# V8M-Generic register map
Vendor: ARM Ltd.
CPU: V8M-Generic r0p0, little endian, MPU, FPU, double-precision FPU, VTOR, vendor SysTick, 8 interrupt priority bits
Registers are 32-bit, read-write, no defined reset value unless marked. A register's access mark holds for its fields unless they carry their own. Offsets are from the block's base; [hi:lo] are bit positions; {n}, {i} and the like mark numbered series; 'fields as' and 'values as' point back to an identical list.

## SCB — System Control Block
Base ?
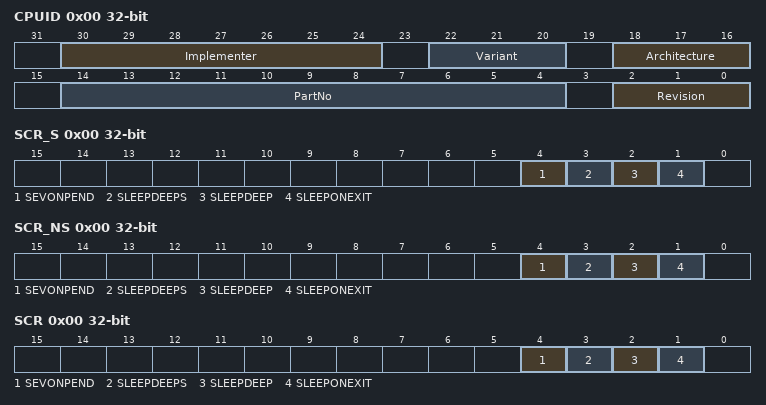
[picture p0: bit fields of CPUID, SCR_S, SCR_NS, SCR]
0x00 CPUID ro
  [30:24] Implementer — Implementer code
  [22:20] Variant — Variant number
  [18:16] Architecture — Architecture version
  [14:4] PartNo — Part number
  [2:0] Revision — Revision number
0x00 SCR_S
  [4] SEVONPEND — Send event on pend
  [3] SLEEPDEEPS — Sleep deep secure
  [2] SLEEPDEEP
  [1] SLEEPONEXIT
0x00 SCR_NS
  fields as SCR_S
0x00 SCR
  fields as SCR_S
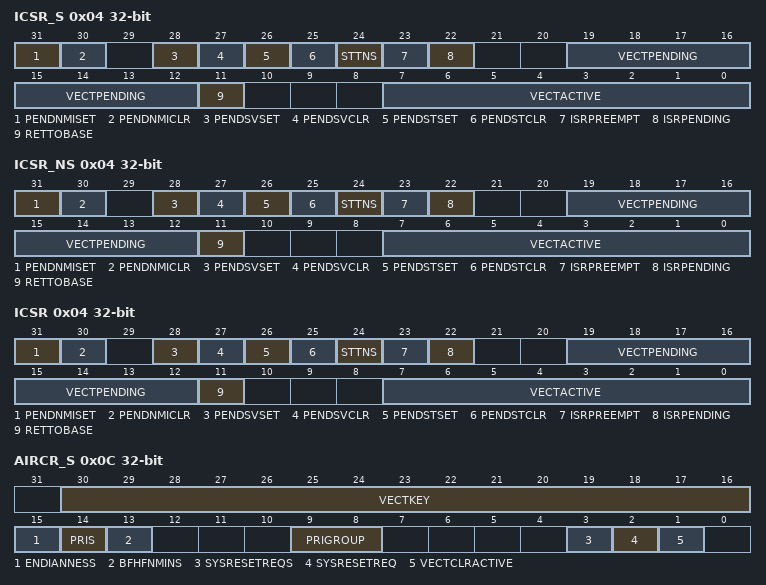
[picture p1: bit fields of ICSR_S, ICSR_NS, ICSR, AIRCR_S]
0x04 ICSR_S
  [31] PENDNMISET
  [30] PENDNMICLR — Pend NMI clear
  [28] PENDSVSET — Pend PendSV set
  [27] PENDSVCLR — Pend PendSV clear
  [26] PENDSTSET — Pend SysTick set
  [25] PENDSTCLR — Pend SysTick clear
  [24] STTNS — SysTick Targets Non-secure
  [23] ISRPREEMPT — Interrupt preempt
  [22] ISRPENDING — Interrupt pending
  [19:12] VECTPENDING — Vector pending
  [11] RETTOBASE — Return to base
  [7:0] VECTACTIVE — Vector active
0x04 ICSR_NS
  fields as ICSR_S
0x04 ICSR
  fields as ICSR_S
0x08 VTOR_S
  [30:7] TBLOFF — Table offset
0x08 VTOR_NS
  [30:7] TBLOFF — Table offset
0x08 VTOR
  [30:7] TBLOFF — Table offset
0x0C AIRCR_S
  [30:16] VECTKEY — Vector key
  [15] ENDIANNESS — Data endianness
  [14] PRIS — Prioritize Secure exceptions
  [13] BFHFNMINS — BusFault, HardFault, and NMI Non-secure enable
  [9:8] PRIGROUP — Priority grouping
  [3] SYSRESETREQS — System reset request Secure only
  [2] SYSRESETREQ — System reset request
  [1] VECTCLRACTIVE — Clear active state
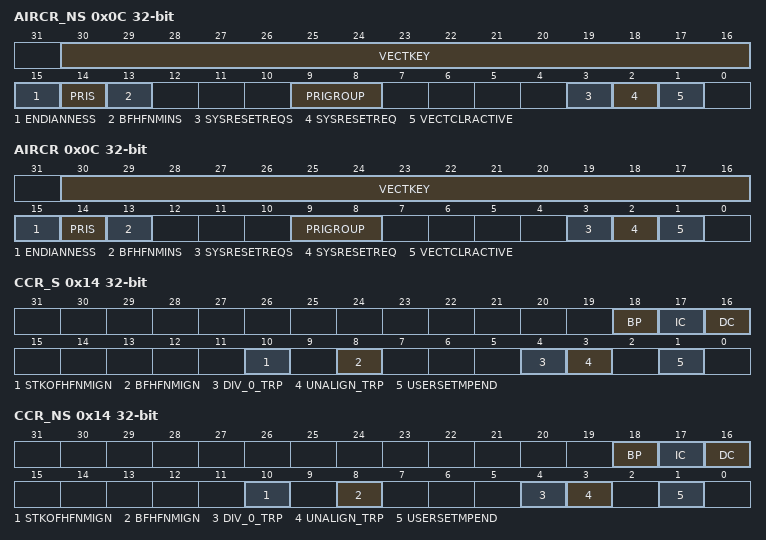
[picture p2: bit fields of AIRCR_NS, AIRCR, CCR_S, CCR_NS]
0x0C AIRCR_NS
  fields as AIRCR_S
0x0C AIRCR
  fields as AIRCR_S
0x14 CCR_S
  [18] BP — Branch prediction enable
  [17] IC — Instruction cache enable
  [16] DC — Data cache enable
  [10] STKOFHFNMIGN — Stack overflow in HardFault and NMI ignore
  [8] BFHFNMIGN — BusFault in HardFault or NMI ignore
  [4] DIV_0_TRP — Divide by zero trap
  [3] UNALIGN_TRP — Unaligned trap
  [1] USERSETMPEND — User set main pending
0x14 CCR_NS
  fields as CCR_S
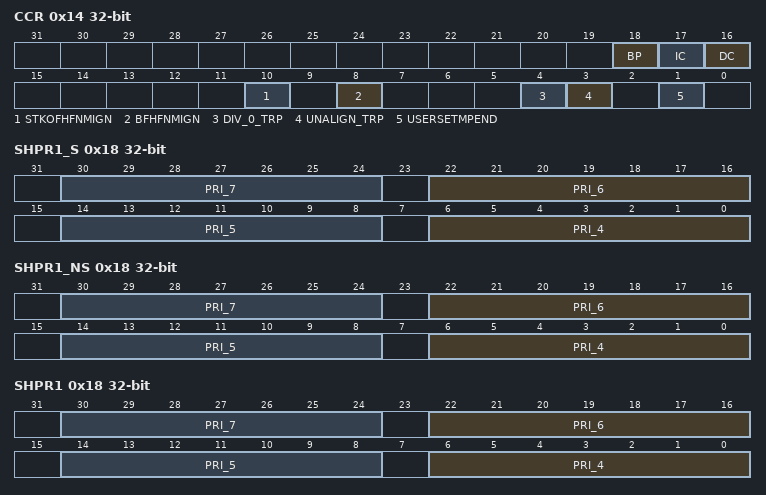
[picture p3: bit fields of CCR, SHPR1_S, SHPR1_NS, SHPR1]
0x14 CCR
  fields as CCR_S
0x18 SHPR1_S
  [8n-26:8n-32] PRI_{n} (n=4..7) — Priority {n}
0x18 SHPR1_NS
  [8n-26:8n-32] PRI_{n} (n=4..7) — Priority {n}
0x18 SHPR1
  [8n-26:8n-32] PRI_{n} (n=4..7) — Priority {n}
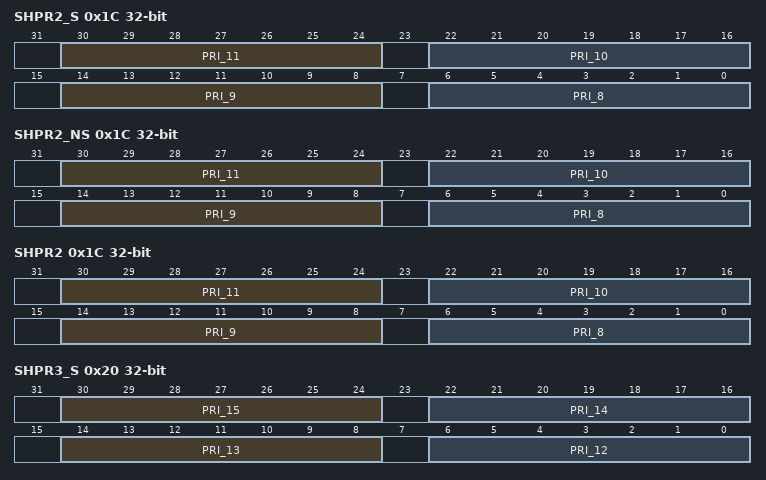
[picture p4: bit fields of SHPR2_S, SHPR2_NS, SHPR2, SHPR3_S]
0x1C SHPR2_S
  [30:24] PRI_11 — Priority 11
  [22:16] PRI_10
  [14:8] PRI_9
  [6:0] PRI_8
0x1C SHPR2_NS
  fields as SHPR2_S
0x1C SHPR2
  fields as SHPR2_S
0x20 SHPR3_S
  [30:24] PRI_15 — Priority 15
  [22:16] PRI_14 — Priority 14
  [14:8] PRI_13
  [6:0] PRI_12 — Priority 12
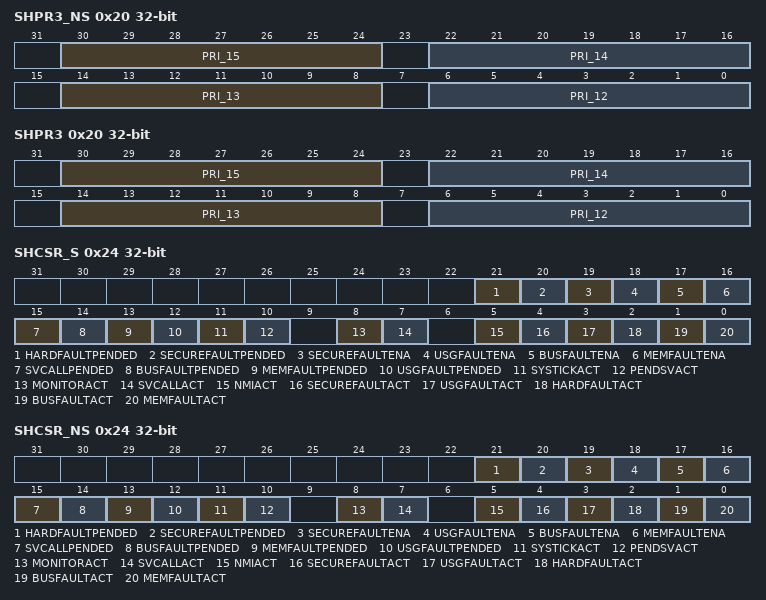
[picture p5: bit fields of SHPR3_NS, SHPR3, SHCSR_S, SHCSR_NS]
0x20 SHPR3_NS
  fields as SHPR3_S
0x20 SHPR3
  fields as SHPR3_S
0x24 SHCSR_S
  [21] HARDFAULTPENDED — HardFault exception pended state
  [20] SECUREFAULTPENDED — SecureFault exception pended state
  [19] SECUREFAULTENA — SecureFault exception enable
  [18] USGFAULTENA — UsageFault exception enable
  [17] BUSFAULTENA — BusFault exception enable
  [16] MEMFAULTENA — MemManage exception enable
  [15] SVCALLPENDED — SVCall exception pended state
  [14] BUSFAULTPENDED — BusFault exception pended state
  [13] MEMFAULTPENDED — MemManage exception pended state
  [12] USGFAULTPENDED — UsageFault exception pended state
  [11] SYSTICKACT — SysTick exception active state
  [10] PENDSVACT — PendSV exception active state
  [8] MONITORACT — DebugMonitor exception active state
  [7] SVCALLACT — SVCall exception active state
  [5] NMIACT — NMI exception active state
  [4] SECUREFAULTACT — SecureFault exception active state
  [3] USGFAULTACT — UsageFault exception active state FTSSS
  [2] HARDFAULTACT — HardFault exception active state
  [1] BUSFAULTACT — BusFault exception active state
  [0] MEMFAULTACT — MemManage exception active state FTSSS
0x24 SHCSR_NS
  fields as SHCSR_S
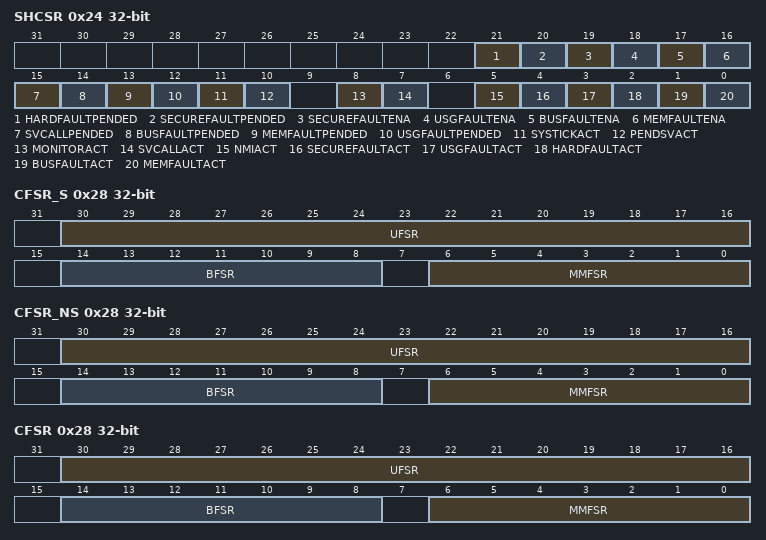
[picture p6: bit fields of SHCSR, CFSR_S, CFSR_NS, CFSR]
0x24 SHCSR
  fields as SHCSR_S
0x28 CFSR_S
  [30:16] UFSR — UsageFault Status Register
  [14:8] BFSR — BusFault Status Register
  [6:0] MMFSR — MemManage Fault Status Register
0x28 CFSR_NS
  fields as CFSR_S
0x28 CFSR
  fields as CFSR_S
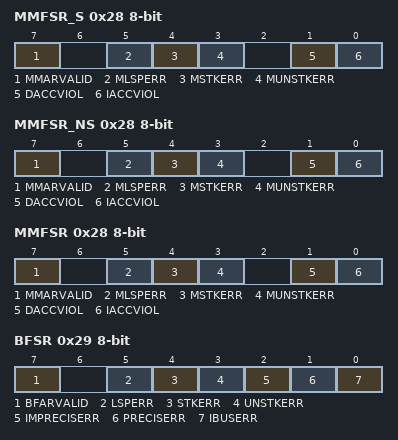
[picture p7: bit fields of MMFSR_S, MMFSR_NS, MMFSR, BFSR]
0x28 MMFSR_S 8-bit
  [7] MMARVALID — MMFAR valid flag
  [5] MLSPERR — MemManage lazy state preservation error flag
  [4] MSTKERR — MemManage stacking error flag
  [3] MUNSTKERR — MemManage unstacking error flag
  [1] DACCVIOL — Data access violation flag
  [0] IACCVIOL — Instruction access violation
0x28 MMFSR_NS 8-bit
  fields as MMFSR_S
0x28 MMFSR 8-bit
  fields as MMFSR_S
0x29 BFSR 8-bit
  [7] BFARVALID
  [5] LSPERR — Lazy state preservation error
  [4] STKERR — Stack error
  [3] UNSTKERR — Unstack error
  [2] IMPRECISERR — Imprecise error
  [1] PRECISERR — Precise error
  [0] IBUSERR — Instruction bus error
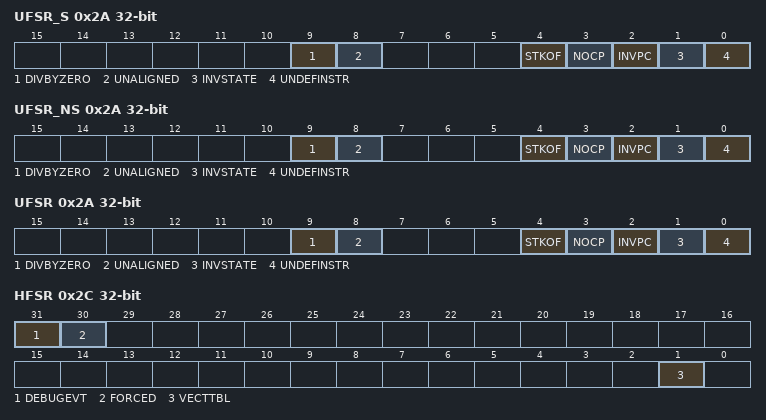
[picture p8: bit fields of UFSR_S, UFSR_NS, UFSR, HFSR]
0x2A UFSR_S size not given
  [9] DIVBYZERO — Divide by zero flag
  [8] UNALIGNED — Unaligned access flag
  [4] STKOF — Stack overflow flag
  [3] NOCP — No coprocessor flag
  [2] INVPC — Invalid PC flag
  [1] INVSTATE — Invalid state flag
  [0] UNDEFINSTR — Undefined instruction flag
0x2A UFSR_NS size not given
  fields as UFSR_S
0x2A UFSR size not given
  fields as UFSR_S
0x2C HFSR
  [31] DEBUGEVT — Debug event
  [30] FORCED
  [1] VECTTBL — Vector table
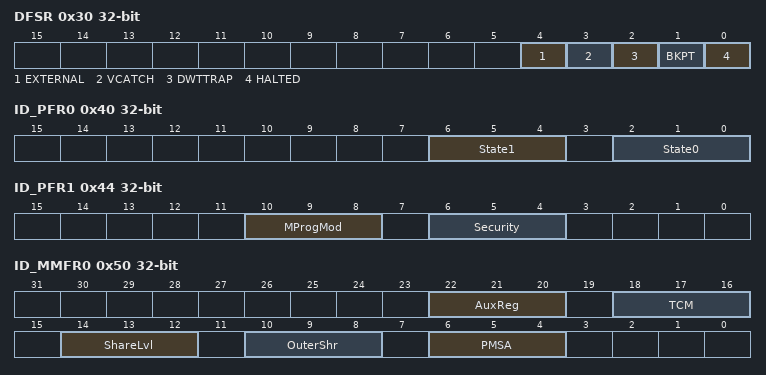
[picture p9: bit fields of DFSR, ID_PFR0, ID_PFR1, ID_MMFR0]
0x30 DFSR
  [4] EXTERNAL — External event
  [3] VCATCH — Vector Catch event
  [2] DWTTRAP — Watchpoint event
  [1] BKPT — Breakpoint event
  [0] HALTED — Halt or step event
0x34 MMFAR_S
  [30:0] ADDRESS — Data address for an MemManage fault
0x34 MMFAR_NS
  [30:0] ADDRESS — Data address for an MemManage fault
0x34 MMFAR
  [30:0] ADDRESS — Data address for an MemManage fault
0x38 BFAR
  [30:0] ADDRESS — Data address for a precise BusFault
0x3C AFSR
0x40 ID_PFR0 ro
  [6:4] State1 — State one
  [2:0] State0 — State two
0x44 ID_PFR1 ro
  [10:8] MProgMod — M programmers' model
  [6:4] Security
0x48 ID_DFR0 ro
  [22:20] MProfDbg — M-profile debug
0x4C ID_AFR0 ro
0x50 ID_MMFR0 ro
  [22:20] AuxReg — Auxiliary Registers
  [18:16] TCM — Tightly coupled memories
  [14:12] ShareLvl — Shareability Levels
  [10:8] OuterShr — Outermost Shareability
  [6:4] PMSA — Protected memory system architecture
0x54 ID_MMFR1 ro
0x58 ID_MMFR2 ro
  [26:24] WFIStall
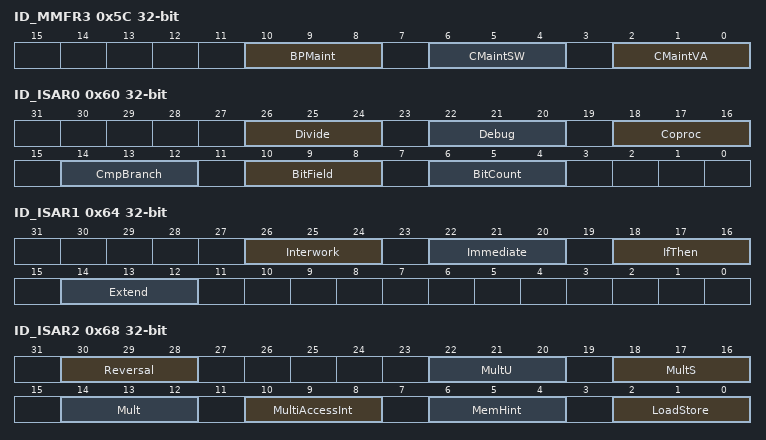
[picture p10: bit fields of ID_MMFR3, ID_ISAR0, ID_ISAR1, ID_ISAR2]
0x5C ID_MMFR3 ro
  [10:8] BPMaint — Branch predictor maintenance
  [6:4] CMaintSW — Cache maintenance set/way
  [2:0] CMaintVA — Cache maintenance by address
0x60 ID_ISAR0 ro
  [26:24] Divide
  [22:20] Debug
  [18:16] Coproc — Coprocessor
  [14:12] CmpBranch — Compare and branch
  [10:8] BitField
  [6:4] BitCount
0x64 ID_ISAR1 ro
  [26:24] Interwork — Interworking
  [22:20] Immediate
  [18:16] IfThen
  [14:12] Extend
0x68 ID_ISAR2 ro
  [30:28] Reversal
  [22:20] MultU — Multiply unsigned
  [18:16] MultS — Multiply signed
  [14:12] Mult — Multiplies
  [10:8] MultiAccessInt — Multi-access instructions
  [6:4] MemHint — Memory hints
  [2:0] LoadStore
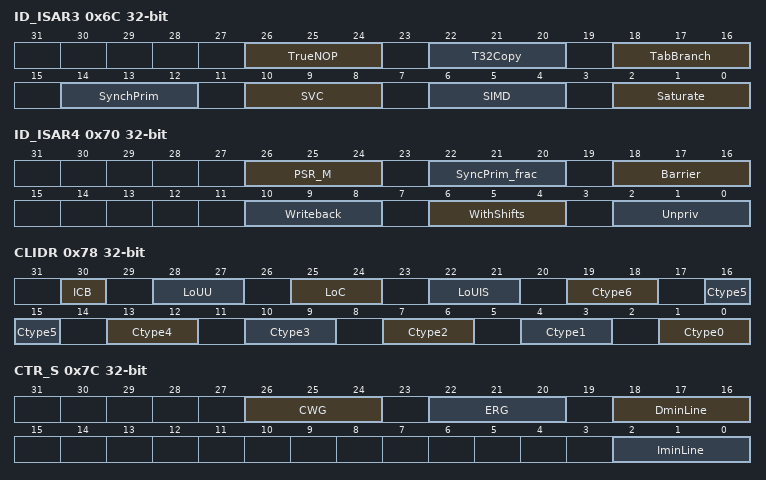
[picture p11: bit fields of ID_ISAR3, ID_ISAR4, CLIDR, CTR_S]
0x6C ID_ISAR3 ro
  [26:24] TrueNOP — True no-operation
  [22:20] T32Copy
  [18:16] TabBranch — Table branch
  [14:12] SynchPrim — Synchronization primitives
  [10:8] SVC — Supervisor call
  [6:4] SIMD — Single-instruction, multiple-data
  [2:0] Saturate
0x70 ID_ISAR4 ro
  [26:24] PSR_M — Program status registers M
  [22:20] SyncPrim_frac — Synchronization primitives fractional
  [18:16] Barrier
  [10:8] Writeback
  [6:4] WithShifts
  [2:0] Unpriv — Unprivileged
0x74 ID_ISAR5 ro
0x78 CLIDR ro
  [30] ICB — Inner cache boundary
  [28:27] LoUU — Level of Unification Uniprocessor
  [25:24] LoC — Level of Coherence
  [22:21] LoUIS — Level of Unification Inner Shareable
  [3n+1:3n] Ctype{n} (n=0..6) — Cache type field {n}
0x7C CTR_S ro
  [26:24] CWG — Cache Writeback Granule
  [22:20] ERG — Exclusives Reservation Granule
  [18:16] DminLine — Data cache minimum line length
  [2:0] IminLine — Instruction cache minimum line length
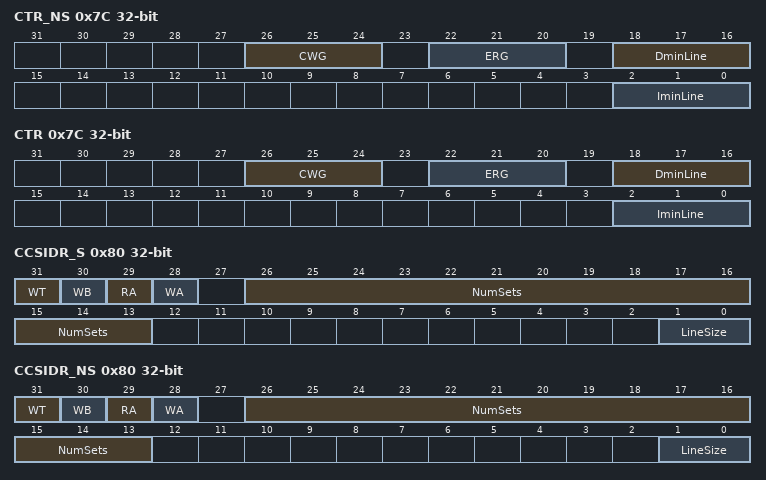
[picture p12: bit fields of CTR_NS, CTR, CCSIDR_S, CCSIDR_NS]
0x7C CTR_NS ro
  fields as CTR_S
0x7C CTR ro
  fields as CTR_S
0x80 CCSIDR_S ro
  [31] WT — Write-through
  [30] WB — Writeback
  [29] RA — Read-allocate
  [28] WA — Write-allocate
  [26:13] NumSets — Number of sets
  [1:0] LineSize
0x80 CCSIDR_NS ro
  fields as CCSIDR_S
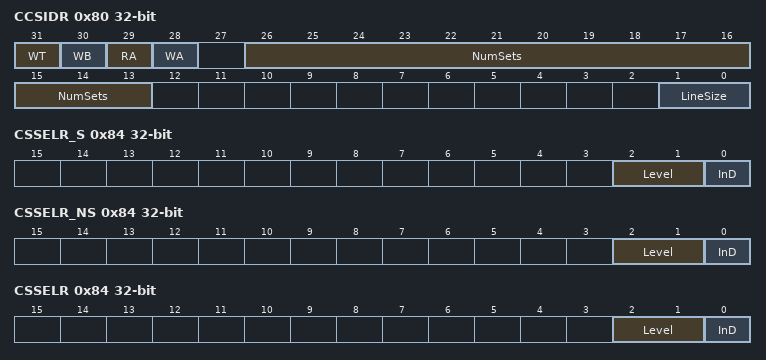
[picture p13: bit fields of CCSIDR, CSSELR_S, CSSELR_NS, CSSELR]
0x80 CCSIDR ro
  fields as CCSIDR_S
0x84 CSSELR_S
  [2:1] Level — Cache level
  [0] InD — Instruction not data
0x84 CSSELR_NS
  [2:1] Level — Cache level
  [0] InD — Instruction not data
0x84 CSSELR
  [2:1] Level — Cache level
  [0] InD — Instruction not data
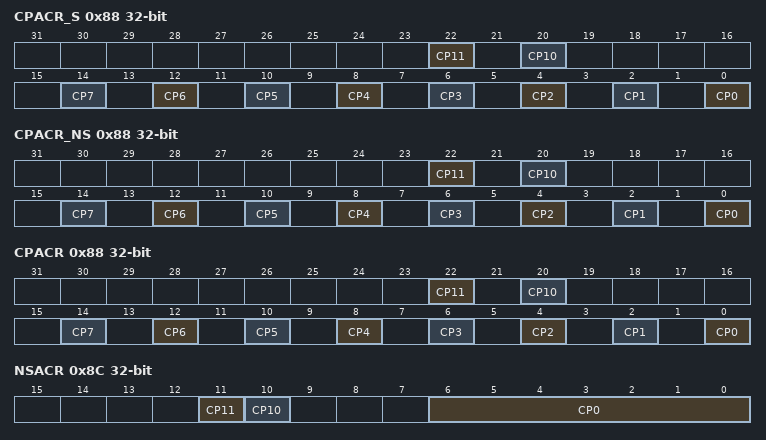
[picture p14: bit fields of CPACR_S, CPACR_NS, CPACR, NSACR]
0x88 CPACR_S
  [22] CP11 — CP11 Privilege
  [20] CP10 — CP10 Privilege
  [2n] CP{n} (n=0..7) — Coprocessor {n} privilege
0x88 CPACR_NS
  fields as CPACR_S
0x88 CPACR
  fields as CPACR_S
0x8C NSACR
  [11] CP11 — CP11 access
  [10] CP10 — CP10 access
  [6:0] CP0 — CP0 access
